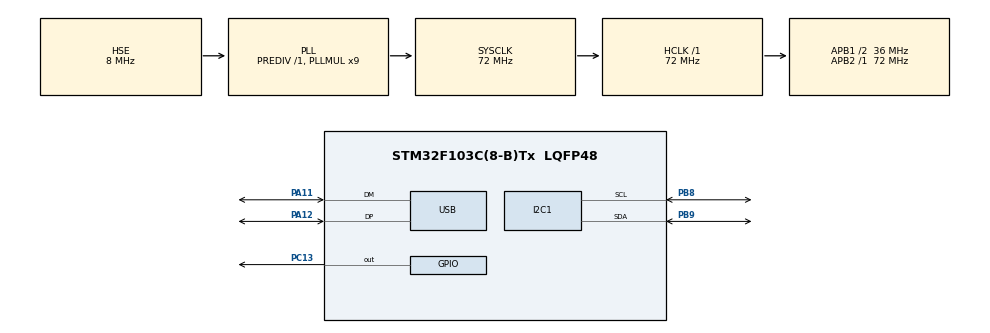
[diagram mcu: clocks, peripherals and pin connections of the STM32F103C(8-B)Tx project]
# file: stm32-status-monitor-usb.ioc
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FREERTOS.Queues01=messageQueue,16,Status,0,Dynamic,NULL,NULL
FREERTOS.Tasks01=defaultTask,24,128,StartDefaultTask,Default,NULL,Dynamic,NULL,NULL;displayTask,24,128,StartDisplayTask,Default,NULL,Dynamic,NULL,NULL
Mcu.Family=STM32F1
Mcu.Name=STM32F103C(8-B)Tx
Mcu.Package=LQFP48
NVIC.PriorityGroup=NVIC_PRIORITYGROUP_4
NVIC.TIM2_IRQn=true\:0\:0\:false\:false\:true\:false\:false\:true
NVIC.TimeBase=TIM2_IRQn
NVIC.TimeBaseIP=TIM2
NVIC.USB_LP_CAN1_RX0_IRQn=true\:5\:0\:false\:false\:true\:true\:false\:true
PA11.Mode=Device
PA11.Signal=USB_DM
PA12.Mode=Device
PA12.Signal=USB_DP
PA13.Mode=Serial_Wire
PA13.Signal=SYS_JTMS-SWDIO
PA14.Mode=Serial_Wire
PA14.Signal=SYS_JTCK-SWCLK
PB8.Mode=I2C
PB8.Signal=I2C1_SCL
PB9.Mode=I2C
PB9.Signal=I2C1_SDA
PC13-TAMPER-RTC.GPIO_ModeDefaultOutputPP=GPIO_MODE_OUTPUT_OD
PC13-TAMPER-RTC.GPIO_Speed=GPIO_SPEED_FREQ_LOW
PC13-TAMPER-RTC.PinState=GPIO_PIN_SET
PC13-TAMPER-RTC.Signal=GPIO_Output
PD0-OSC_IN.Mode=HSE-External-Oscillator
PD0-OSC_IN.Signal=RCC_OSC_IN
PD1-OSC_OUT.Mode=HSE-External-Oscillator
PD1-OSC_OUT.Signal=RCC_OSC_OUT
ProjectManager.HeapSize=0x200
ProjectManager.StackSize=0x400
ProjectManager.TargetToolchain=Makefile
RCC.AHBFreq_Value=72000000
RCC.APB1CLKDivider=RCC_HCLK_DIV2
RCC.APB1Freq_Value=36000000
RCC.APB1TimFreq_Value=72000000
RCC.APB2Freq_Value=72000000
RCC.APB2TimFreq_Value=72000000
RCC.HCLKFreq_Value=72000000
RCC.PLLMUL=RCC_PLL_MUL9
RCC.SYSCLKFreq_VALUE=72000000
RCC.SYSCLKSource=RCC_SYSCLKSOURCE_PLLCLK
RCC.USBFreq_Value=48000000
RCC.USBPrescaler=RCC_USBCLKSOURCE_PLL_DIV1_5
USB_DEVICE.CLASS_NAME_FS=CDC
USB_DEVICE.MANUFACTURER_STRING=Marco Satti
USB_DEVICE.PRODUCT_STRING_CDC_FS=Status Monitor
USB_DEVICE.VirtualMode=Cdc
USB_DEVICE.VirtualModeFS=Cdc_FS
VP_FREERTOS_VS_CMSIS_V2.Mode=CMSIS_V2
VP_SYS_VS_tim2.Mode=TIM2
VP_USB_DEVICE_VS_USB_DEVICE_CDC_FS.Mode=CDC_FS
board=custom

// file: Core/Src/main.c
/* USER CODE BEGIN Header */
/**
  ******************************************************************************
  * @file           : main.c
  * @brief          : Main program body
  ******************************************************************************
  * @attention
  *
  * <h2><center>&copy; Copyright (c) 2021 STMicroelectronics.
  * All rights reserved.</center></h2>
  *
  * This software component is licensed by ST under Ultimate Liberty license
  * SLA0044, the "License"; You may not use this file except in compliance with
  * the License. You may obtain a copy of the License at:
  *                             www.st.com/SLA0044
  *
  ******************************************************************************
  */
/* USER CODE END Header */
#include "main.h"
#include "cmsis_os.h"
#include "usb_device.h"

/* USER CODE BEGIN Includes */
#include "status.pb.h"
#include "display.h"
/* USER CODE END Includes */

I2C_HandleTypeDef hi2c1;

/* Definitions for defaultTask */
osThreadId_t defaultTaskHandle;
const osThreadAttr_t defaultTask_attributes = {
  .name = "defaultTask",
  .stack_size = 128 * 4,
  .priority = (osPriority_t) osPriorityNormal,
};
/* Definitions for displayTask */
osThreadId_t displayTaskHandle;
const osThreadAttr_t displayTask_attributes = {
  .name = "displayTask",
  .stack_size = 128 * 4,
  .priority = (osPriority_t) osPriorityNormal,
};
/* Definitions for messageQueue */
osMessageQueueId_t messageQueueHandle;
const osMessageQueueAttr_t messageQueue_attributes = {
  .name = "messageQueue"
};

void SystemClock_Config(void);
static void MX_GPIO_Init(void);
static void MX_I2C1_Init(void);
void StartDefaultTask(void *argument);
void StartDisplayTask(void *argument);

int main(void)
{

  /* MCU Configuration--------------------------------------------------------*/

  /* Reset of all peripherals, Initializes the Flash interface and the Systick. */
  HAL_Init();

  /* Configure the system clock */
  SystemClock_Config();

  /* Initialize all configured peripherals */
  MX_GPIO_Init();
  MX_I2C1_Init();

  /* Init scheduler */
  osKernelInitialize();

  /* Create the queue(s) */
  /* creation of messageQueue */
  messageQueueHandle = osMessageQueueNew (16, sizeof(Status), &messageQueue_attributes);

  /* Create the thread(s) */
  /* creation of defaultTask */
  defaultTaskHandle = osThreadNew(StartDefaultTask, NULL, &defaultTask_attributes);

  /* creation of displayTask */
  displayTaskHandle = osThreadNew(StartDisplayTask, NULL, &displayTask_attributes);

  /* Start scheduler */
  osKernelStart();

  /* We should never get here as control is now taken by the scheduler */
  /* Infinite loop */
  while (1)
  {

  }
}

void SystemClock_Config(void)
{
  RCC_OscInitTypeDef RCC_OscInitStruct = {0};
  RCC_ClkInitTypeDef RCC_ClkInitStruct = {0};
  RCC_PeriphCLKInitTypeDef PeriphClkInit = {0};

  /** Initializes the RCC Oscillators according to the specified parameters
  * in the RCC_OscInitTypeDef structure.
  */
  RCC_OscInitStruct.OscillatorType = RCC_OSCILLATORTYPE_HSE;
  RCC_OscInitStruct.HSEState = RCC_HSE_ON;
  RCC_OscInitStruct.HSEPredivValue = RCC_HSE_PREDIV_DIV1;
  RCC_OscInitStruct.HSIState = RCC_HSI_ON;
  RCC_OscInitStruct.PLL.PLLState = RCC_PLL_ON;
  RCC_OscInitStruct.PLL.PLLSource = RCC_PLLSOURCE_HSE;
  RCC_OscInitStruct.PLL.PLLMUL = RCC_PLL_MUL9;
  if (HAL_RCC_OscConfig(&RCC_OscInitStruct) != HAL_OK)
  {
    Error_Handler();
  }
  /** Initializes the CPU, AHB and APB buses clocks
  */
  RCC_ClkInitStruct.ClockType = RCC_CLOCKTYPE_HCLK|RCC_CLOCKTYPE_SYSCLK
                              |RCC_CLOCKTYPE_PCLK1|RCC_CLOCKTYPE_PCLK2;
  RCC_ClkInitStruct.SYSCLKSource = RCC_SYSCLKSOURCE_PLLCLK;
  RCC_ClkInitStruct.AHBCLKDivider = RCC_SYSCLK_DIV1;
  RCC_ClkInitStruct.APB1CLKDivider = RCC_HCLK_DIV2;
  RCC_ClkInitStruct.APB2CLKDivider = RCC_HCLK_DIV1;

  if (HAL_RCC_ClockConfig(&RCC_ClkInitStruct, FLASH_LATENCY_2) != HAL_OK)
  {
    Error_Handler();
  }
  PeriphClkInit.PeriphClockSelection = RCC_PERIPHCLK_USB;
  PeriphClkInit.UsbClockSelection = RCC_USBCLKSOURCE_PLL_DIV1_5;
  if (HAL_RCCEx_PeriphCLKConfig(&PeriphClkInit) != HAL_OK)
  {
    Error_Handler();
  }
}

static void MX_I2C1_Init(void)
{

  hi2c1.Instance = I2C1;
  hi2c1.Init.ClockSpeed = 100000;
  hi2c1.Init.DutyCycle = I2C_DUTYCYCLE_2;
  hi2c1.Init.OwnAddress1 = 0;
  hi2c1.Init.AddressingMode = I2C_ADDRESSINGMODE_7BIT;
  hi2c1.Init.DualAddressMode = I2C_DUALADDRESS_DISABLE;
  hi2c1.Init.OwnAddress2 = 0;
  hi2c1.Init.GeneralCallMode = I2C_GENERALCALL_DISABLE;
  hi2c1.Init.NoStretchMode = I2C_NOSTRETCH_DISABLE;
  if (HAL_I2C_Init(&hi2c1) != HAL_OK)
  {
    Error_Handler();
  }

}

static void MX_GPIO_Init(void)
{
  GPIO_InitTypeDef GPIO_InitStruct = {0};

  /* GPIO Ports Clock Enable */
  __HAL_RCC_GPIOC_CLK_ENABLE();
  __HAL_RCC_GPIOD_CLK_ENABLE();
  __HAL_RCC_GPIOA_CLK_ENABLE();
  __HAL_RCC_GPIOB_CLK_ENABLE();

  /*Configure GPIO pin Output Level */
  HAL_GPIO_WritePin(GPIOC, GPIO_PIN_13, GPIO_PIN_SET);

  /*Configure GPIO pin : PC13 */
  GPIO_InitStruct.Pin = GPIO_PIN_13;
  GPIO_InitStruct.Mode = GPIO_MODE_OUTPUT_OD;
  GPIO_InitStruct.Pull = GPIO_NOPULL;
  GPIO_InitStruct.Speed = GPIO_SPEED_FREQ_LOW;
  HAL_GPIO_Init(GPIOC, &GPIO_InitStruct);

}

void StartDefaultTask(void *argument)
{
  /* init code for USB_DEVICE */
  MX_USB_DEVICE_Init();
  /* USER CODE BEGIN 5 */
  /* Infinite loop */
  for(;;)
  {
    osDelay(1000);
  }
  /* USER CODE END 5 */
}

void StartDisplayTask(void *argument)
{
  /* USER CODE BEGIN StartDisplayTask */
  display_task_main();
  /* USER CODE END StartDisplayTask */
}

 /**
  * @brief  Period elapsed callback in non blocking mode
  * @note   This function is called  when TIM2 interrupt took place, inside
  * HAL_TIM_IRQHandler(). It makes a direct call to HAL_IncTick() to increment
  * a global variable "uwTick" used as application time base.
  * @param  htim : TIM handle
  * @retval None
  */
void HAL_TIM_PeriodElapsedCallback(TIM_HandleTypeDef *htim)
{
  if (htim->Instance == TIM2) {
    HAL_IncTick();
  }
}

void Error_Handler(void)
{
  /* USER CODE BEGIN Error_Handler_Debug */
  /* User can add his own implementation to report the HAL error return state */
  __disable_irq();

  HAL_GPIO_WritePin(GPIOC, GPIO_PIN_13, GPIO_PIN_RESET);

  while (1)
  {
  }
  /* USER CODE END Error_Handler_Debug */
}

/************************ (C) COPYRIGHT STMicroelectronics *****END OF FILE****/
